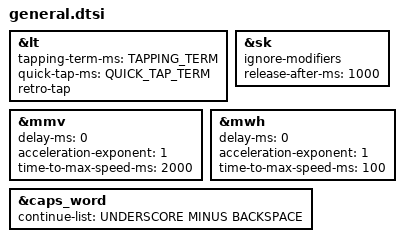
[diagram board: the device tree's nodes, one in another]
#include <behaviors.dtsi>
#include <dt-bindings/zmk/keys.h>
#include <dt-bindings/zmk/bt.h>
#include <dt-bindings/zmk/outputs.h>
#include <dt-bindings/zmk/mouse.h>

#define COLE    0
#define GAME    1
#define GAMET   2
#define NAV     3
#define MOUSE   4
#define MEDIA   5
#define NUM     6
#define SYM     7
#define FUN     8
#define NOTHING 9

#define TAPPING_TERM 175
#define TAPPING_TERM_RING 225
#define TAPPING_TERM_PINKY 275
#define QUICK_TAP_TERM 300

&lt {
    tapping-term-ms = <TAPPING_TERM>;
    quick-tap-ms = <QUICK_TAP_TERM>;
    retro-tap;
};

&sk {
    ignore-modifiers;
    release-after-ms = <1000>;
};

&mmv {
    delay-ms = <0>;
    acceleration-exponent=<1>;
    time-to-max-speed-ms = <2000>;
};

&mwh {
    delay-ms = <0>;
    acceleration-exponent=<1>;
    time-to-max-speed-ms = <100>;
};

&caps_word {
  continue-list = <UNDERSCORE MINUS BACKSPACE>;
};
